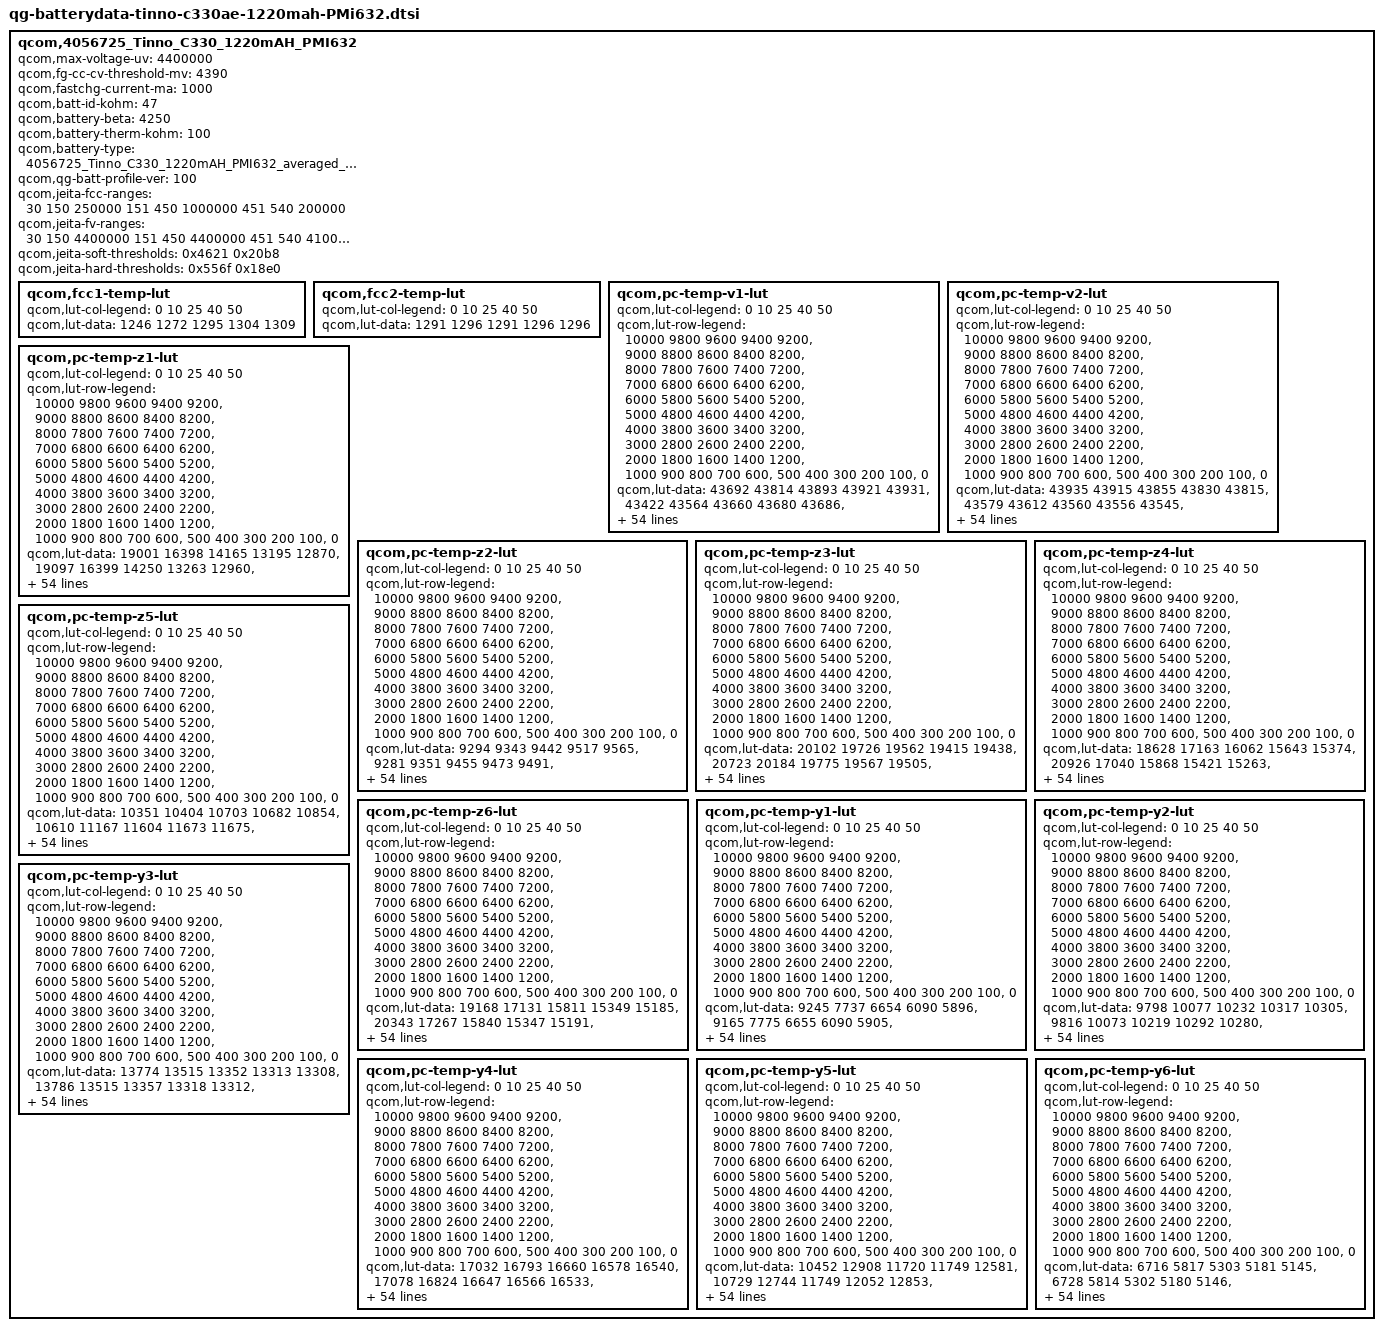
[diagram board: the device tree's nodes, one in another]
qcom,4056725_Tinno_C330_1220mAH_PMI632 {
    /* 4056725_Tinno_C330_1220mAH_PMI632_averaged_MasterSlave_Jul8th2019 */
    qcom,max-voltage-uv = <4400000>;
	qcom,fg-cc-cv-threshold-mv = <4390>;
	qcom,fastchg-current-ma = <1000>;
    qcom,batt-id-kohm = <47>;
    qcom,battery-beta = <4250>;
    qcom,battery-therm-kohm = <100>;
    qcom,battery-type = "4056725_Tinno_C330_1220mAH_PMI632_averaged_MasterSlave_Jul8th2019";
    qcom,qg-batt-profile-ver = <100>;

	qcom,jeita-fcc-ranges = <30   150   250000
				 151 450  1000000
				 451 540  200000>;
	qcom,jeita-fv-ranges =  <30   150  4400000
				 151 450  4400000
				 451 540  4100000>;

	/* COOL = 15 DegC, WARM = 45 DegC */
	qcom,jeita-soft-thresholds = <0x4621 0x20b8>;
	/* COLD = 3 DegC, HOT = 54 DegC */
	qcom,jeita-hard-thresholds = <0x556f 0x18e0>;
	qcom,fcc1-temp-lut {
		qcom,lut-col-legend = <0 10 25 40 50>;
		qcom,lut-data = <1246 1272 1295 1304 1309>;
	};

	qcom,fcc2-temp-lut {
		qcom,lut-col-legend = <0 10 25 40 50>;
		qcom,lut-data = <1291 1296 1291 1296 1296>;
	};

	qcom,pc-temp-v1-lut {
		qcom,lut-col-legend = <0 10 25 40 50>;
		qcom,lut-row-legend = <10000 9800 9600 9400 9200>,
			<9000 8800 8600 8400 8200>,
			<8000 7800 7600 7400 7200>,
			<7000 6800 6600 6400 6200>,
			<6000 5800 5600 5400 5200>,
			<5000 4800 4600 4400 4200>,
			<4000 3800 3600 3400 3200>,
			<3000 2800 2600 2400 2200>,
			<2000 1800 1600 1400 1200>,
			<1000 900 800 700 600>,
			<500 400 300 200 100>,
			<0>;
		qcom,lut-data = <43692 43814 43893 43921 43931>,
			<43422 43564 43660 43680 43686>,
			<43154 43303 43415 43441 43445>,
			<42907 43056 43166 43199 43211>,
			<42667 42812 42919 42961 42969>,
			<42434 42572 42676 42718 42728>,
			<42208 42335 42435 42477 42491>,
			<41992 42105 42196 42239 42255>,
			<41783 41884 41962 42003 42022>,
			<41576 41668 41734 41771 41790>,
			<41371 41455 41510 41541 41561>,
			<41174 41246 41288 41317 41336>,
			<41003 41056 41075 41096 41114>,
			<40828 40896 40889 40886 40899>,
			<40575 40716 40721 40685 40689>,
			<40228 40425 40522 40488 40487>,
			<39974 40094 40249 40288 40293>,
			<39834 39912 40006 40093 40107>,
			<39722 39807 39858 39918 39931>,
			<39608 39697 39734 39756 39763>,
			<39497 39565 39576 39580 39587>,
			<39382 39414 39390 39383 39391>,
			<39258 39222 39193 39187 39196>,
			<39132 38992 38964 38989 39002>,
			<39007 38804 38767 38807 38819>,
			<38883 38647 38651 38672 38677>,
			<38759 38528 38562 38563 38560>,
			<38630 38453 38476 38462 38455>,
			<38517 38395 38394 38367 38358>,
			<38426 38345 38319 38281 38270>,
			<38352 38302 38247 38206 38191>,
			<38299 38262 38181 38137 38119>,
			<38260 38223 38130 38079 38055>,
			<38227 38186 38084 38027 37997>,
			<38200 38153 38042 37977 37942>,
			<38175 38121 38003 37929 37890>,
			<38144 38085 37962 37879 37835>,
			<38110 38047 37924 37828 37772>,
			<38066 37999 37878 37769 37701>,
			<37998 37915 37803 37692 37619>,
			<37908 37801 37693 37591 37521>,
			<37794 37682 37575 37477 37410>,
			<37650 37550 37440 37341 37276>,
			<37491 37400 37290 37192 37128>,
			<37351 37255 37146 37048 36984>,
			<37251 37162 37062 36971 36911>,
			<37210 37139 37041 36951 36890>,
			<37181 37117 37026 36935 36876>,
			<37154 37094 37006 36916 36858>,
			<37111 37045 36949 36843 36770>,
			<36904 36813 36698 36567 36478>,
			<36482 36382 36258 36120 36031>,
			<35913 35814 35688 35546 35453>,
			<35134 35042 34910 34763 34663>,
			<33924 33848 33705 33548 33442>,
			<30000 30000 30000 30000 30000>;
	};

	qcom,pc-temp-v2-lut {
		qcom,lut-col-legend = <0 10 25 40 50>;
		qcom,lut-row-legend = <10000 9800 9600 9400 9200>,
			<9000 8800 8600 8400 8200>,
			<8000 7800 7600 7400 7200>,
			<7000 6800 6600 6400 6200>,
			<6000 5800 5600 5400 5200>,
			<5000 4800 4600 4400 4200>,
			<4000 3800 3600 3400 3200>,
			<3000 2800 2600 2400 2200>,
			<2000 1800 1600 1400 1200>,
			<1000 900 800 700 600>,
			<500 400 300 200 100>,
			<0>;
		qcom,lut-data = <43935 43915 43855 43830 43815>,
			<43579 43612 43560 43556 43545>,
			<43257 43326 43282 43292 43283>,
			<42976 43058 43021 43040 43034>,
			<42726 42807 42778 42798 42794>,
			<42482 42562 42537 42559 42556>,
			<42238 42323 42300 42322 42320>,
			<42004 42089 42066 42087 42086>,
			<41790 41862 41837 41856 41855>,
			<41584 41640 41612 41628 41627>,
			<41367 41422 41388 41403 41402>,
			<41140 41207 41164 41182 41180>,
			<40937 41016 40962 40967 40963>,
			<40785 40866 40802 40762 40753>,
			<40612 40697 40633 40560 40548>,
			<40258 40396 40376 40354 40350>,
			<39786 40021 40073 40151 40159>,
			<39542 39767 39881 39966 39975>,
			<39418 39586 39763 39798 39799>,
			<39295 39412 39624 39618 39617>,
			<39141 39236 39394 39411 39421>,
			<38982 39067 39144 39200 39222>,
			<38831 38910 38953 39001 39018>,
			<38683 38760 38788 38812 38819>,
			<38549 38627 38646 38658 38660>,
			<38429 38507 38522 38531 38533>,
			<38313 38396 38412 38419 38420>,
			<38187 38295 38309 38318 38319>,
			<38072 38201 38217 38226 38228>,
			<37993 38106 38132 38142 38140>,
			<37934 38016 38056 38065 38060>,
			<37885 37937 37986 37992 37987>,
			<37845 37863 37924 37922 37924>,
			<37807 37805 37864 37854 37857>,
			<37768 37767 37809 37788 37779>,
			<37727 37734 37754 37718 37692>,
			<37681 37699 37694 37636 37592>,
			<37628 37662 37630 37542 37480>,
			<37569 37611 37561 37457 37386>,
			<37505 37535 37485 37381 37310>,
			<37428 37452 37401 37299 37228>,
			<37330 37358 37303 37205 37136>,
			<37225 37239 37180 37081 37015>,
			<37121 37089 37046 36948 36883>,
			<37027 36968 36917 36838 36776>,
			<36952 36920 36888 36815 36759>,
			<36922 36901 36874 36803 36746>,
			<36889 36876 36855 36785 36727>,
			<36832 36834 36818 36734 36671>,
			<36686 36685 36674 36543 36458>,
			<36355 36296 36317 36146 36047>,
			<35835 35758 35814 35634 35535>,
			<35135 35063 35182 34982 34878>,
			<34153 34166 34378 34153 34061>,
			<32804 33026 33136 32885 32762>,
			<31116 31059 31453 30005 29920>;
	};

	qcom,pc-temp-z1-lut {
		qcom,lut-col-legend = <0 10 25 40 50>;
		qcom,lut-row-legend = <10000 9800 9600 9400 9200>,
			<9000 8800 8600 8400 8200>,
			<8000 7800 7600 7400 7200>,
			<7000 6800 6600 6400 6200>,
			<6000 5800 5600 5400 5200>,
			<5000 4800 4600 4400 4200>,
			<4000 3800 3600 3400 3200>,
			<3000 2800 2600 2400 2200>,
			<2000 1800 1600 1400 1200>,
			<1000 900 800 700 600>,
			<500 400 300 200 100>,
			<0>;
		qcom,lut-data = <19001 16398 14165 13195 12870>,
			<19097 16399 14250 13263 12960>,
			<19047 16424 14229 13267 12968>,
			<19045 16393 14184 13250 12954>,
			<19029 16360 14151 13232 12948>,
			<19001 16326 14132 13220 12944>,
			<18979 16290 14123 13215 12940>,
			<18959 16269 14115 13213 12936>,
			<18936 16258 14112 13210 12932>,
			<18928 16252 14107 13203 12928>,
			<18928 16258 14104 13194 12925>,
			<18921 16276 14104 13194 12922>,
			<18856 16279 14103 13195 12920>,
			<18750 16239 14093 13195 12917>,
			<18657 16189 14060 13183 12915>,
			<18546 16140 14036 13174 12913>,
			<18502 16094 14020 13174 12912>,
			<18513 16086 14012 13174 12911>,
			<18532 16099 14025 13176 12912>,
			<18550 16116 14049 13181 12912>,
			<18574 16148 14068 13182 12913>,
			<18609 16184 14083 13181 12915>,
			<18691 16209 14095 13180 12917>,
			<18756 16229 14103 13184 12919>,
			<18745 16247 14110 13191 12922>,
			<18712 16264 14118 13199 12928>,
			<18708 16276 14127 13210 12937>,
			<18766 16282 14137 13220 12944>,
			<18817 16283 14155 13230 12949>,
			<18797 16288 14169 13238 12952>,
			<18755 16312 14179 13245 12958>,
			<18756 16324 14190 13251 12964>,
			<18803 16327 14199 13258 12966>,
			<18855 16333 14207 13265 12970>,
			<18900 16361 14217 13271 12973>,
			<18939 16414 14230 13278 12979>,
			<18959 16436 14242 13285 12984>,
			<18969 16461 14260 13291 12989>,
			<18990 16484 14277 13297 12992>,
			<19036 16511 14285 13303 12995>,
			<19077 16550 14294 13310 12997>,
			<19068 16584 14301 13316 13000>,
			<19034 16614 14311 13321 13006>,
			<19004 16590 14330 13325 13009>,
			<18959 16545 14351 13329 13010>,
			<18984 16518 14345 13336 13014>,
			<18966 16530 14347 13340 13016>,
			<18964 16523 14343 13345 13019>,
			<18979 16551 14367 13347 13022>,
			<19000 16572 14374 13361 13029>,
			<19002 16556 14389 13364 13041>,
			<19042 16624 14406 13380 13052>,
			<19131 16694 14441 13406 13073>,
			<19166 16780 14499 13437 13100>,
			<19166 16780 14499 13437 13100>,
			<19166 16780 14499 13437 13100>;
	};

	qcom,pc-temp-z2-lut {
		qcom,lut-col-legend = <0 10 25 40 50>;
		qcom,lut-row-legend = <10000 9800 9600 9400 9200>,
			<9000 8800 8600 8400 8200>,
			<8000 7800 7600 7400 7200>,
			<7000 6800 6600 6400 6200>,
			<6000 5800 5600 5400 5200>,
			<5000 4800 4600 4400 4200>,
			<4000 3800 3600 3400 3200>,
			<3000 2800 2600 2400 2200>,
			<2000 1800 1600 1400 1200>,
			<1000 900 800 700 600>,
			<500 400 300 200 100>,
			<0>;
		qcom,lut-data = <9294 9343 9442 9517 9565>,
			<9281 9351 9455 9473 9491>,
			<9302 9355 9458 9529 9489>,
			<9325 9350 9435 9512 9494>,
			<9331 9339 9413 9505 9538>,
			<9332 9333 9402 9501 9531>,
			<9332 9331 9404 9500 9527>,
			<9329 9329 9413 9504 9525>,
			<9323 9325 9419 9508 9521>,
			<9319 9322 9424 9510 9499>,
			<9317 9320 9428 9513 9467>,
			<9315 9318 9431 9507 9465>,
			<9312 9318 9435 9492 9475>,
			<9309 9325 9441 9488 9488>,
			<9304 9330 9451 9490 9508>,
			<9297 9330 9454 9489 9524>,
			<9292 9329 9447 9485 9529>,
			<9291 9331 9442 9482 9533>,
			<9290 9346 9446 9487 9536>,
			<9290 9358 9455 9507 9540>,
			<9291 9363 9466 9533 9548>,
			<9291 9367 9480 9573 9579>,
			<9289 9373 9485 9595 9603>,
			<9287 9380 9481 9556 9595>,
			<9288 9381 9477 9504 9580>,
			<9292 9375 9475 9524 9586>,
			<9296 9369 9473 9596 9604>,
			<9302 9370 9476 9613 9607>,
			<9307 9373 9491 9565 9553>,
			<9309 9374 9498 9519 9502>,
			<9310 9377 9477 9497 9486>,
			<9312 9380 9457 9483 9475>,
			<9315 9385 9457 9485 9478>,
			<9318 9389 9461 9499 9495>,
			<9321 9391 9465 9518 9515>,
			<9324 9393 9475 9555 9539>,
			<9328 9395 9484 9582 9561>,
			<9335 9396 9489 9587 9580>,
			<9342 9399 9495 9589 9594>,
			<9348 9404 9504 9594 9596>,
			<9355 9412 9515 9603 9596>,
			<9361 9414 9519 9604 9596>,
			<9366 9415 9517 9596 9596>,
			<9377 9419 9515 9585 9589>,
			<9367 9439 9515 9574 9575>,
			<9395 9503 9535 9574 9592>,
			<9411 9535 9528 9577 9583>,
			<9349 9578 9528 9563 9583>,
			<9392 9616 9533 9572 9625>,
			<9345 9624 9551 9597 9616>,
			<9402 9583 9587 9559 9529>,
			<9310 9551 9571 9516 9507>,
			<9258 9514 9574 9474 9481>,
			<9283 9474 9512 9441 9425>,
			<9283 9474 9512 9441 9425>,
			<9283 9474 9512 9441 9425>;
	};

	qcom,pc-temp-z3-lut {
		qcom,lut-col-legend = <0 10 25 40 50>;
		qcom,lut-row-legend = <10000 9800 9600 9400 9200>,
			<9000 8800 8600 8400 8200>,
			<8000 7800 7600 7400 7200>,
			<7000 6800 6600 6400 6200>,
			<6000 5800 5600 5400 5200>,
			<5000 4800 4600 4400 4200>,
			<4000 3800 3600 3400 3200>,
			<3000 2800 2600 2400 2200>,
			<2000 1800 1600 1400 1200>,
			<1000 900 800 700 600>,
			<500 400 300 200 100>,
			<0>;
		qcom,lut-data = <20102 19726 19562 19415 19438>,
			<20723 20184 19775 19567 19505>,
			<20828 20462 19822 19591 19536>,
			<20852 20559 20028 19667 19523>,
			<20843 20598 20039 19759 19701>,
			<20750 20604 20038 19743 19679>,
			<20677 20595 20019 19723 19654>,
			<20672 20586 19971 19697 19631>,
			<20672 20573 19932 19674 19606>,
			<20679 20552 19901 19657 19578>,
			<20702 20520 19876 19638 19549>,
			<20719 20466 19861 19617 19532>,
			<20717 20395 19848 19592 19516>,
			<20715 20270 19809 19572 19507>,
			<20765 20189 19739 19549 19500>,
			<20933 20236 19718 19535 19493>,
			<21013 20320 19754 19535 19481>,
			<20938 20311 19783 19535 19467>,
			<20833 20196 19766 19530 19455>,
			<20774 20136 19740 19517 19445>,
			<20728 20152 19744 19517 19444>,
			<20718 20179 19774 19550 19469>,
			<20760 20214 19786 19573 19490>,
			<20803 20257 19784 19546 19472>,
			<20816 20268 19779 19510 19443>,
			<20824 20260 19753 19516 19462>,
			<20833 20249 19710 19552 19546>,
			<20848 20238 19709 19587 19582>,
			<20857 20226 19741 19626 19577>,
			<20850 20212 19776 19645 19568>,
			<20830 20196 19817 19635 19550>,
			<20806 20186 19846 19615 19525>,
			<20772 20183 19835 19597 19513>,
			<20733 20180 19805 19579 19503>,
			<20690 20176 19787 19568 19496>,
			<20642 20171 19776 19561 19486>,
			<20585 20164 19766 19557 19479>,
			<20514 20149 19755 19555 19482>,
			<20465 20136 19744 19552 19486>,
			<20438 20126 19733 19545 19486>,
			<20414 20115 19722 19531 19483>,
			<20392 20102 19715 19523 19479>,
			<20370 20084 19710 19520 19469>,
			<20341 20053 19702 19516 19467>,
			<20107 19986 19681 19510 19470>,
			<19503 19830 19635 19481 19440>,
			<19494 19614 19600 19470 19433>,
			<19392 19486 19560 19469 19433>,
			<19427 19448 19575 19457 19398>,
			<19308 19423 19544 19451 19418>,
			<19467 19490 19493 19485 19466>,
			<19399 19499 19494 19504 19451>,
			<19404 19493 19473 19523 19471>,
			<19518 19503 19504 19543 19516>,
			<19518 19503 19504 19543 19516>,
			<19518 19503 19504 19543 19516>;
	};

	qcom,pc-temp-z4-lut {
		qcom,lut-col-legend = <0 10 25 40 50>;
		qcom,lut-row-legend = <10000 9800 9600 9400 9200>,
			<9000 8800 8600 8400 8200>,
			<8000 7800 7600 7400 7200>,
			<7000 6800 6600 6400 6200>,
			<6000 5800 5600 5400 5200>,
			<5000 4800 4600 4400 4200>,
			<4000 3800 3600 3400 3200>,
			<3000 2800 2600 2400 2200>,
			<2000 1800 1600 1400 1200>,
			<1000 900 800 700 600>,
			<500 400 300 200 100>,
			<0>;
		qcom,lut-data = <18628 17163 16062 15643 15374>,
			<20926 17040 15868 15421 15263>,
			<21170 17567 15482 15182 15079>,
			<20160 17413 15913 15204 15005>,
			<19366 16751 15755 15368 15207>,
			<18754 16342 15511 15224 15125>,
			<18233 16072 15379 15158 15075>,
			<17803 15851 15283 15137 15060>,
			<17436 15641 15229 15119 15051>,
			<17136 15481 15197 15093 15044>,
			<16890 15409 15175 15069 15038>,
			<16659 15364 15159 15057 15028>,
			<16408 15333 15145 15045 15006>,
			<16187 15307 15123 15032 14983>,
			<16057 15291 15091 15008 14956>,
			<15968 15285 15069 14982 14931>,
			<15881 15281 15046 14952 14914>,
			<15784 15259 15020 14926 14900>,
			<15688 15180 14977 14915 14892>,
			<15596 15106 14931 14908 14886>,
			<15506 15047 14934 14911 14887>,
			<15417 15009 14981 14961 14935>,
			<15311 15071 15057 15039 15014>,
			<15239 15264 15266 15196 15147>,
			<15226 15408 15428 15354 15288>,
			<15220 15519 15427 15345 15273>,
			<15224 15575 15413 15265 15143>,
			<15272 15546 15379 15181 15053>,
			<15321 15482 15283 15087 15005>,
			<15342 15422 15188 15017 14972>,
			<15358 15359 15102 14983 14950>,
			<15354 15298 15037 14959 14931>,
			<15319 15237 15011 14939 14912>,
			<15278 15181 14996 14922 14892>,
			<15239 15133 14988 14919 14888>,
			<15206 15091 14983 14930 14907>,
			<15193 15060 14982 14944 14932>,
			<15186 15034 14984 14963 14958>,
			<15178 15022 14988 14982 14979>,
			<15151 15033 15000 14991 14979>,
			<15124 15050 15018 14997 14970>,
			<15118 15045 15018 14996 14959>,
			<15115 15018 14995 14977 14943>,
			<15092 15008 14985 14972 14941>,
			<15205 14989 14975 14974 14946>,
			<15594 14940 14866 14881 14862>,
			<15589 15153 14869 14846 14830>,
			<15670 15262 14862 14787 14770>,
			<15611 15277 14807 14760 14757>,
			<15701 15289 14845 14795 14769>,
			<15567 15273 14972 14807 14773>,
			<15715 15303 14996 14803 14790>,
			<15774 15339 15032 14790 14771>,
			<15723 15367 15017 14779 14740>,
			<15723 15367 15017 14779 14740>,
			<15723 15367 15017 14779 14740>;
	};

	qcom,pc-temp-z5-lut {
		qcom,lut-col-legend = <0 10 25 40 50>;
		qcom,lut-row-legend = <10000 9800 9600 9400 9200>,
			<9000 8800 8600 8400 8200>,
			<8000 7800 7600 7400 7200>,
			<7000 6800 6600 6400 6200>,
			<6000 5800 5600 5400 5200>,
			<5000 4800 4600 4400 4200>,
			<4000 3800 3600 3400 3200>,
			<3000 2800 2600 2400 2200>,
			<2000 1800 1600 1400 1200>,
			<1000 900 800 700 600>,
			<500 400 300 200 100>,
			<0>;
		qcom,lut-data = <10351 10404 10703 10682 10854>,
			<10610 11167 11604 11673 11675>,
			<10701 11224 12399 12386 12608>,
			<10849 11227 11851 12772 12817>,
			<10949 11435 11958 12269 12904>,
			<11018 11614 12144 12538 13069>,
			<11077 11780 12328 12622 13124>,
			<11136 11982 12550 12526 12953>,
			<11199 12364 12613 12464 12722>,
			<11269 12745 12609 12449 12476>,
			<11352 12888 12607 12422 12223>,
			<11408 12972 12653 12362 12155>,
			<11415 12942 12711 12231 12140>,
			<11418 12381 12591 12192 12171>,
			<11608 11928 12189 12150 12314>,
			<12227 12396 12076 12162 12431>,
			<12519 13214 12514 12394 12435>,
			<12247 13319 13157 12724 12430>,
			<11941 13104 13858 12937 12463>,
			<11945 13012 14736 13108 12576>,
			<12069 14285 15884 13513 12766>,
			<12302 16507 17410 14842 13525>,
			<13150 19112 17917 15678 14104>,
			<14299 22169 17207 14357 13212>,
			<15351 22872 16150 12499 11764>,
			<16505 21307 14720 12146 11683>,
			<17869 19489 13136 12031 12147>,
			<19808 18264 12882 12074 12520>,
			<21014 17216 12951 12723 12890>,
			<21002 16492 13106 13444 13139>,
			<20775 15905 14345 13900 13274>,
			<20391 15702 15795 14319 13491>,
			<19513 15862 16348 14796 13882>,
			<18531 16161 16719 15331 14725>,
			<17576 16606 17208 15834 15120>,
			<16604 17226 17954 16385 15162>,
			<15639 17571 18289 16664 15101>,
			<14584 17761 17859 16354 14911>,
			<14097 17841 17160 15717 14615>,
			<14175 18006 16462 14980 14284>,
			<14310 18246 15678 14071 13857>,
			<14363 18090 15362 13639 13494>,
			<14486 17367 15242 13497 13174>,
			<14748 16369 14888 13252 12940>,
			<13913 15484 14440 12942 12778>,
			<10500 14185 14779 13234 12814>,
			<10469 11471 13886 13188 13011>,
			<10308 10664 12754 14108 14032>,
			<10335 10554 13562 14513 13541>,
			<10193 10510 12748 13222 13314>,
			<10488 10712 11417 12856 13749>,
			<10325 10664 11208 12926 12649>,
			<10280 10576 10999 13401 13776>,
			<10352 10519 11090 14051 15997>,
			<10352 10519 11090 14051 15997>,
			<10352 10519 11090 14051 15997>;
	};

	qcom,pc-temp-z6-lut {
		qcom,lut-col-legend = <0 10 25 40 50>;
		qcom,lut-row-legend = <10000 9800 9600 9400 9200>,
			<9000 8800 8600 8400 8200>,
			<8000 7800 7600 7400 7200>,
			<7000 6800 6600 6400 6200>,
			<6000 5800 5600 5400 5200>,
			<5000 4800 4600 4400 4200>,
			<4000 3800 3600 3400 3200>,
			<3000 2800 2600 2400 2200>,
			<2000 1800 1600 1400 1200>,
			<1000 900 800 700 600>,
			<500 400 300 200 100>,
			<0>;
		qcom,lut-data = <19168 17131 15811 15349 15185>,
			<20343 17267 15840 15347 15191>,
			<20451 17592 15692 15253 15129>,
			<19949 17536 15977 15299 15091>,
			<19528 17243 15910 15423 15277>,
			<19167 17045 15801 15352 15228>,
			<18864 16900 15724 15308 15191>,
			<18636 16777 15657 15286 15171>,
			<18450 16665 15612 15266 15154>,
			<18299 16573 15581 15243 15135>,
			<18176 16513 15559 15221 15117>,
			<18056 16469 15544 15202 15099>,
			<17893 16413 15530 15185 15082>,
			<17757 16322 15495 15165 15065>,
			<17736 16265 15434 15142 15049>,
			<17734 16278 15414 15122 15034>,
			<17729 16302 15418 15108 15019>,
			<17659 16288 15420 15097 15005>,
			<17562 16196 15400 15087 14994>,
			<17498 16146 15368 15078 14986>,
			<17445 16144 15370 15079 14985>,
			<17425 16145 15405 15116 15018>,
			<17421 16186 15453 15165 15065>,
			<17420 16300 15545 15223 15116>,
			<17425 16374 15611 15270 15162>,
			<17438 16421 15602 15271 15166>,
			<17458 16444 15579 15259 15155>,
			<17495 16431 15559 15245 15142>,
			<17523 16403 15540 15226 15122>,
			<17530 16376 15523 15206 15101>,
			<17534 16347 15510 15187 15080>,
			<17531 16320 15498 15167 15060>,
			<17505 16296 15481 15148 15044>,
			<17476 16276 15463 15131 15029>,
			<17450 16260 15452 15126 15025>,
			<17425 16247 15444 15128 15027>,
			<17402 16239 15441 15130 15031>,
			<17380 16234 15439 15137 15042>,
			<17365 16231 15439 15144 15055>,
			<17358 16240 15441 15144 15056>,
			<17353 16253 15445 15141 15051>,
			<17350 16254 15445 15136 15044>,
			<17348 16245 15436 15127 15033>,
			<17339 16234 15429 15124 15031>,
			<17287 16204 15420 15123 15036>,
			<17157 16116 15353 15068 14984>,
			<17153 16098 15336 15047 14966>,
			<17142 16083 15311 15022 14940>,
			<17133 16075 15300 15003 14915>,
			<17137 16079 15304 15014 14932>,
			<17175 16116 15336 15045 14964>,
			<17229 16154 15356 15056 14968>,
			<17297 16190 15373 15066 14976>,
			<17381 16247 15396 15081 14991>,
			<17381 16247 15396 15081 14991>,
			<17381 16247 15396 15081 14991>;
	};

	qcom,pc-temp-y1-lut {
		qcom,lut-col-legend = <0 10 25 40 50>;
		qcom,lut-row-legend = <10000 9800 9600 9400 9200>,
			<9000 8800 8600 8400 8200>,
			<8000 7800 7600 7400 7200>,
			<7000 6800 6600 6400 6200>,
			<6000 5800 5600 5400 5200>,
			<5000 4800 4600 4400 4200>,
			<4000 3800 3600 3400 3200>,
			<3000 2800 2600 2400 2200>,
			<2000 1800 1600 1400 1200>,
			<1000 900 800 700 600>,
			<500 400 300 200 100>,
			<0>;
		qcom,lut-data = <9245 7737 6654 6090 5896>,
			<9165 7775 6655 6090 5905>,
			<9083 7800 6653 6089 5912>,
			<9012 7815 6648 6087 5916>,
			<8963 7822 6644 6085 5918>,
			<8951 7823 6639 6082 5918>,
			<8969 7812 6633 6078 5915>,
			<8986 7802 6627 6075 5912>,
			<8976 7802 6620 6073 5911>,
			<8959 7802 6615 6072 5910>,
			<8958 7796 6612 6070 5908>,
			<8961 7776 6611 6066 5906>,
			<8966 7768 6609 6064 5905>,
			<8968 7767 6591 6064 5904>,
			<8970 7767 6574 6064 5903>,
			<8999 7775 6582 6063 5903>,
			<9054 7792 6601 6063 5903>,
			<9068 7807 6611 6063 5904>,
			<9060 7827 6616 6062 5904>,
			<9055 7832 6618 6062 5904>,
			<9050 7820 6615 6062 5905>,
			<9044 7807 6612 6063 5906>,
			<9052 7796 6614 6064 5908>,
			<9071 7784 6621 6066 5909>,
			<9069 7786 6627 6069 5911>,
			<9027 7806 6633 6071 5912>,
			<8994 7816 6638 6074 5913>,
			<8985 7797 6641 6078 5915>,
			<8980 7776 6643 6083 5918>,
			<8984 7776 6655 6088 5922>,
			<9001 7781 6687 6093 5927>,
			<9011 7785 6699 6098 5931>,
			<9008 7807 6685 6101 5935>,
			<8999 7821 6674 6105 5939>,
			<8974 7824 6677 6112 5943>,
			<8942 7825 6680 6120 5947>,
			<8935 7818 6686 6123 5951>,
			<8937 7805 6695 6125 5953>,
			<8937 7802 6705 6128 5956>,
			<8927 7811 6714 6133 5957>,
			<8924 7817 6729 6142 5960>,
			<8939 7821 6755 6152 5964>,
			<9059 7861 6748 6158 5973>,
			<9063 7893 6753 6163 5974>,
			<9104 7942 6771 6171 5982>,
			<9131 7933 6790 6179 5988>,
			<9114 7943 6795 6185 5994>,
			<9150 7917 6799 6185 5990>,
			<9137 7899 6811 6187 5990>,
			<9127 7942 6839 6189 5990>,
			<9151 7926 6842 6194 5998>,
			<9177 7947 6850 6211 6009>,
			<9219 7987 6889 6226 6022>,
			<9271 8060 6942 6251 6040>,
			<9271 8060 6942 6251 6040>,
			<9271 8060 6942 6251 6040>;
	};

	qcom,pc-temp-y2-lut {
		qcom,lut-col-legend = <0 10 25 40 50>;
		qcom,lut-row-legend = <10000 9800 9600 9400 9200>,
			<9000 8800 8600 8400 8200>,
			<8000 7800 7600 7400 7200>,
			<7000 6800 6600 6400 6200>,
			<6000 5800 5600 5400 5200>,
			<5000 4800 4600 4400 4200>,
			<4000 3800 3600 3400 3200>,
			<3000 2800 2600 2400 2200>,
			<2000 1800 1600 1400 1200>,
			<1000 900 800 700 600>,
			<500 400 300 200 100>,
			<0>;
		qcom,lut-data = <9798 10077 10232 10317 10305>,
			<9816 10073 10219 10292 10280>,
			<9834 10066 10207 10261 10253>,
			<9850 10059 10196 10232 10228>,
			<9864 10053 10185 10209 10207>,
			<9876 10050 10175 10198 10195>,
			<9889 10047 10165 10194 10189>,
			<9895 10046 10158 10192 10183>,
			<9888 10048 10158 10192 10171>,
			<9875 10051 10158 10191 10160>,
			<9890 10048 10161 10191 10162>,
			<9962 10038 10171 10192 10181>,
			<10003 10037 10175 10195 10197>,
			<10012 10090 10172 10201 10206>,
			<10017 10138 10169 10210 10217>,
			<10020 10130 10173 10246 10240>,
			<10021 10115 10187 10305 10273>,
			<10026 10114 10209 10331 10303>,
			<10041 10118 10255 10343 10332>,
			<10059 10122 10277 10353 10362>,
			<10080 10126 10259 10361 10401>,
			<10097 10131 10236 10367 10428>,
			<10101 10134 10229 10339 10394>,
			<10102 10137 10225 10279 10323>,
			<10101 10141 10225 10266 10303>,
			<10093 10147 10231 10285 10299>,
			<10087 10152 10238 10297 10301>,
			<10084 10157 10246 10303 10370>,
			<10083 10159 10253 10315 10443>,
			<10080 10159 10256 10335 10430>,
			<10077 10156 10258 10370 10393>,
			<10072 10153 10259 10386 10387>,
			<10065 10150 10259 10401 10414>,
			<10056 10147 10258 10408 10432>,
			<9985 10141 10256 10389 10417>,
			<9875 10134 10252 10357 10390>,
			<9818 10129 10247 10328 10366>,
			<9710 10124 10239 10293 10325>,
			<9662 10117 10228 10280 10298>,
			<9658 10103 10214 10280 10278>,
			<9656 10088 10201 10278 10275>,
			<9654 10072 10192 10274 10277>,
			<9653 10066 10189 10246 10286>,
			<9654 10059 10193 10263 10275>,
			<9653 10017 10163 10204 10227>,
			<9651 9985 10135 10177 10168>,
			<9650 9973 10138 10181 10155>,
			<9650 9953 10132 10178 10166>,
			<9650 9953 10132 10174 10158>,
			<9649 9938 10127 10162 10160>,
			<9649 9713 10107 10154 10130>,
			<9649 9668 10095 10145 10140>,
			<9648 9657 10074 10137 10118>,
			<9648 9655 10072 10132 10124>,
			<9648 9655 10072 10132 10124>,
			<9648 9655 10072 10132 10124>;
	};

	qcom,pc-temp-y3-lut {
		qcom,lut-col-legend = <0 10 25 40 50>;
		qcom,lut-row-legend = <10000 9800 9600 9400 9200>,
			<9000 8800 8600 8400 8200>,
			<8000 7800 7600 7400 7200>,
			<7000 6800 6600 6400 6200>,
			<6000 5800 5600 5400 5200>,
			<5000 4800 4600 4400 4200>,
			<4000 3800 3600 3400 3200>,
			<3000 2800 2600 2400 2200>,
			<2000 1800 1600 1400 1200>,
			<1000 900 800 700 600>,
			<500 400 300 200 100>,
			<0>;
		qcom,lut-data = <13774 13515 13352 13313 13308>,
			<13786 13515 13357 13318 13312>,
			<13796 13516 13362 13323 13315>,
			<13802 13519 13367 13328 13319>,
			<13805 13522 13372 13332 13322>,
			<13806 13527 13377 13337 13326>,
			<13801 13534 13381 13341 13329>,
			<13797 13538 13386 13345 13333>,
			<13804 13536 13393 13348 13337>,
			<13817 13534 13400 13352 13340>,
			<13827 13539 13403 13357 13344>,
			<13837 13561 13406 13365 13347>,
			<13836 13577 13408 13369 13349>,
			<13732 13587 13414 13374 13350>,
			<13630 13593 13419 13378 13350>,
			<13631 13566 13410 13378 13355>,
			<13639 13517 13391 13376 13363>,
			<13639 13504 13390 13372 13362>,
			<13630 13501 13406 13356 13350>,
			<13619 13498 13414 13346 13340>,
			<13608 13489 13401 13344 13336>,
			<13595 13480 13383 13342 13332>,
			<13579 13473 13376 13335 13323>,
			<13562 13467 13371 13325 13311>,
			<13557 13465 13368 13321 13308>,
			<13556 13464 13366 13320 13308>,
			<13555 13463 13365 13319 13309>,
			<13538 13462 13365 13319 13315>,
			<13514 13461 13364 13318 13320>,
			<13506 13460 13365 13320 13317>,
			<13502 13459 13365 13321 13310>,
			<13502 13457 13365 13323 13308>,
			<13514 13447 13367 13325 13309>,
			<13531 13442 13370 13326 13310>,
			<13546 13447 13373 13326 13310>,
			<13567 13456 13377 13325 13310>,
			<13598 13466 13377 13323 13308>,
			<13647 13478 13375 13321 13304>,
			<13694 13481 13373 13320 13303>,
			<13734 13480 13370 13322 13307>,
			<13773 13479 13370 13325 13309>,
			<13810 13478 13374 13327 13310>,
			<13815 13469 13365 13321 13315>,
			<13725 13441 13356 13318 13308>,
			<13852 13443 13355 13321 13304>,
			<14042 13470 13374 13336 13328>,
			<14167 13489 13378 13342 13334>,
			<14296 13504 13386 13357 13343>,
			<14412 13531 13400 13355 13340>,
			<14502 13540 13402 13348 13335>,
			<14640 13576 13403 13346 13329>,
			<14853 13683 13416 13361 13343>,
			<15097 13811 13434 13367 13346>,
			<15485 14016 13455 13376 13354>,
			<15485 14016 13455 13376 13354>,
			<15485 14016 13455 13376 13354>;
	};

	qcom,pc-temp-y4-lut {
		qcom,lut-col-legend = <0 10 25 40 50>;
		qcom,lut-row-legend = <10000 9800 9600 9400 9200>,
			<9000 8800 8600 8400 8200>,
			<8000 7800 7600 7400 7200>,
			<7000 6800 6600 6400 6200>,
			<6000 5800 5600 5400 5200>,
			<5000 4800 4600 4400 4200>,
			<4000 3800 3600 3400 3200>,
			<3000 2800 2600 2400 2200>,
			<2000 1800 1600 1400 1200>,
			<1000 900 800 700 600>,
			<500 400 300 200 100>,
			<0>;
		qcom,lut-data = <17032 16793 16660 16578 16540>,
			<17078 16824 16647 16566 16533>,
			<17143 16854 16640 16556 16526>,
			<17211 16881 16636 16549 16518>,
			<17264 16905 16635 16544 16514>,
			<17286 16923 16636 16543 16512>,
			<17293 16935 16643 16546 16514>,
			<17299 16949 16653 16550 16516>,
			<17316 16988 16662 16558 16520>,
			<17335 17031 16673 16568 16527>,
			<17331 17031 16687 16576 16535>,
			<17300 17010 16713 16586 16546>,
			<17299 17009 16748 16594 16559>,
			<17646 17158 16818 16612 16580>,
			<17985 17291 16880 16635 16601>,
			<17684 17222 16895 16661 16614>,
			<17047 17071 16903 16693 16627>,
			<16922 16983 16916 16741 16659>,
			<17001 16925 16936 16816 16730>,
			<17045 16883 16944 16846 16760>,
			<17023 16853 16849 16795 16742>,
			<16988 16828 16721 16721 16710>,
			<16960 16804 16665 16656 16654>,
			<16932 16783 16629 16596 16583>,
			<16899 16771 16621 16582 16564>,
			<16857 16763 16623 16581 16561>,
			<16824 16757 16626 16582 16560>,
			<16802 16754 16634 16597 16564>,
			<16787 16751 16647 16621 16574>,
			<16793 16734 16662 16643 16599>,
			<16815 16705 16681 16666 16642>,
			<16828 16699 16697 16682 16677>,
			<16832 16702 16712 16695 16708>,
			<16837 16708 16720 16701 16721>,
			<16872 16725 16716 16697 16706>,
			<16929 16748 16706 16689 16678>,
			<16971 16771 16694 16662 16635>,
			<17025 16795 16676 16609 16577>,
			<17048 16803 16665 16587 16561>,
			<17046 16806 16659 16581 16559>,
			<17036 16806 16651 16582 16563>,
			<17007 16802 16633 16587 16571>,
			<16992 16748 16625 16574 16541>,
			<16957 16695 16584 16549 16524>,
			<16955 16706 16560 16506 16503>,
			<16998 16736 16580 16538 16519>,
			<17009 16767 16617 16570 16543>,
			<17060 16828 16667 16592 16578>,
			<17122 16895 16710 16641 16627>,
			<17137 16921 16690 16593 16556>,
			<17087 16915 16643 16560 16539>,
			<17067 16943 16659 16584 16575>,
			<17094 17025 16742 16680 16667>,
			<17334 17227 16997 16957 16970>,
			<17334 17227 16997 16957 16970>,
			<17334 17227 16997 16957 16970>;
	};

	qcom,pc-temp-y5-lut {
		qcom,lut-col-legend = <0 10 25 40 50>;
		qcom,lut-row-legend = <10000 9800 9600 9400 9200>,
			<9000 8800 8600 8400 8200>,
			<8000 7800 7600 7400 7200>,
			<7000 6800 6600 6400 6200>,
			<6000 5800 5600 5400 5200>,
			<5000 4800 4600 4400 4200>,
			<4000 3800 3600 3400 3200>,
			<3000 2800 2600 2400 2200>,
			<2000 1800 1600 1400 1200>,
			<1000 900 800 700 600>,
			<500 400 300 200 100>,
			<0>;
		qcom,lut-data = <10452 12908 11720 11749 12581>,
			<10729 12744 11749 12052 12853>,
			<11028 12524 11761 12311 13161>,
			<11312 12304 11759 12508 13443>,
			<11548 12138 11747 12626 13635>,
			<11699 12080 11723 12649 13678>,
			<11781 12081 11629 12582 13632>,
			<11881 12076 11524 12473 13550>,
			<12280 11906 11499 12299 13392>,
			<12816 11660 11523 12085 13141>,
			<12821 11883 11491 11986 12880>,
			<12491 12856 11328 12019 12587>,
			<12340 13237 11231 12036 12262>,
			<12403 12833 11074 11881 11809>,
			<12522 12474 10932 11711 11519>,
			<13162 13466 11078 11607 11584>,
			<14323 15281 11549 11495 11710>,
			<14555 15442 12388 11462 11649>,
			<14073 14685 14219 11451 11273>,
			<13864 14230 15132 11493 11134>,
			<14195 14122 14928 12628 12116>,
			<14542 14057 14616 13758 13080>,
			<14531 13979 14337 13611 12999>,
			<14356 13886 13947 13180 12759>,
			<14449 13908 13631 12884 12626>,
			<15197 14162 13366 12443 12361>,
			<15673 14457 13173 12224 12256>,
			<14308 14752 13038 12044 12470>,
			<12332 15031 12953 11861 12686>,
			<11786 15252 12963 11929 12368>,
			<11534 15434 13043 12101 11606>,
			<11509 15263 13184 12285 11438>,
			<11894 13887 13598 12504 11612>,
			<12280 13049 14121 12729 11866>,
			<12310 13260 14734 13005 12359>,
			<12199 13643 15287 13217 12802>,
			<12077 14083 15218 13191 12760>,
			<11713 14610 14576 13048 12565>,
			<11603 14651 13891 12901 12447>,
			<11703 13848 13123 12711 12334>,
			<11705 13378 12867 12589 12161>,
			<11452 13174 12954 12478 12015>,
			<11022 13115 12201 11955 12704>,
			<10771 12256 12698 12527 13069>,
			<10776 11499 12239 13967 12772>,
			<10678 11680 12710 12790 13425>,
			<10896 11840 12023 11990 12542>,
			<11055 11662 11604 12275 12541>,
			<11263 11962 11663 11779 12051>,
			<11352 12018 12156 12062 12967>,
			<11249 11377 13123 13661 13664>,
			<11159 11371 14579 16246 16773>,
			<11362 11690 15844 17046 17161>,
			<11592 13319 16513 17087 17143>,
			<11592 13319 16513 17087 17143>,
			<11592 13319 16513 17087 17143>;
	};

	qcom,pc-temp-y6-lut {
		qcom,lut-col-legend = <0 10 25 40 50>;
		qcom,lut-row-legend = <10000 9800 9600 9400 9200>,
			<9000 8800 8600 8400 8200>,
			<8000 7800 7600 7400 7200>,
			<7000 6800 6600 6400 6200>,
			<6000 5800 5600 5400 5200>,
			<5000 4800 4600 4400 4200>,
			<4000 3800 3600 3400 3200>,
			<3000 2800 2600 2400 2200>,
			<2000 1800 1600 1400 1200>,
			<1000 900 800 700 600>,
			<500 400 300 200 100>,
			<0>;
		qcom,lut-data = <6716 5817 5303 5181 5145>,
			<6728 5814 5302 5180 5146>,
			<6731 5810 5303 5181 5147>,
			<6727 5807 5305 5182 5149>,
			<6717 5804 5308 5184 5151>,
			<6705 5801 5311 5187 5154>,
			<6681 5798 5315 5191 5157>,
			<6657 5796 5320 5195 5160>,
			<6641 5797 5326 5199 5164>,
			<6626 5798 5333 5204 5168>,
			<6608 5798 5340 5210 5173>,
			<6586 5797 5348 5217 5178>,
			<6579 5800 5358 5224 5184>,
			<6600 5839 5382 5233 5190>,
			<6620 5873 5400 5241 5196>,
			<6547 5837 5397 5249 5204>,
			<6397 5763 5390 5257 5212>,
			<6368 5732 5391 5265 5221>,
			<6390 5718 5408 5274 5230>,
			<6402 5705 5416 5277 5233>,
			<6388 5687 5380 5262 5226>,
			<6367 5671 5330 5238 5212>,
			<6353 5659 5309 5213 5189>,
			<6340 5650 5296 5189 5160>,
			<6338 5648 5293 5183 5152>,
			<6342 5649 5293 5182 5151>,
			<6344 5649 5294 5181 5151>,
			<6340 5653 5296 5186 5156>,
			<6335 5656 5301 5193 5164>,
			<6342 5656 5306 5200 5170>,
			<6369 5654 5313 5209 5177>,
			<6401 5655 5320 5215 5185>,
			<6438 5658 5327 5221 5195>,
			<6481 5664 5332 5223 5200>,
			<6531 5681 5334 5222 5196>,
			<6588 5708 5335 5220 5188>,
			<6651 5737 5334 5211 5175>,
			<6721 5768 5329 5195 5156>,
			<6796 5798 5327 5190 5151>,
			<6878 5825 5326 5190 5153>,
			<6961 5858 5326 5193 5157>,
			<7037 5892 5328 5197 5161>,
			<7083 5890 5323 5189 5156>,
			<7001 5857 5307 5180 5147>,
			<7171 5929 5304 5172 5139>,
			<7388 6037 5329 5193 5162>,
			<7515 6101 5345 5207 5174>,
			<7653 6175 5369 5225 5190>,
			<7782 6273 5395 5238 5203>,
			<7883 6336 5391 5219 5179>,
			<8008 6402 5386 5209 5170>,
			<8198 6569 5408 5229 5192>,
			<8429 6806 5455 5264 5224>,
			<8908 7117 5555 5353 5319>,
			<8908 7117 5555 5353 5319>,
			<8908 7117 5555 5353 5319>;
	};

};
